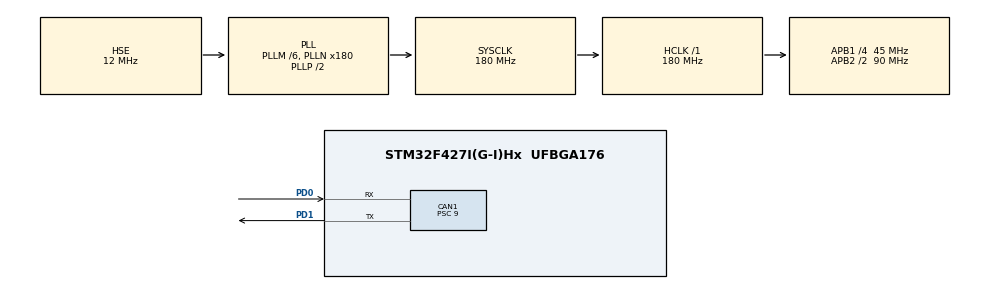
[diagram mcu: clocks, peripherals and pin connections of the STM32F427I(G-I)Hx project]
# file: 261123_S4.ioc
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CAN1.BS1=CAN_BS1_2TQ
CAN1.BS2=CAN_BS2_2TQ
CAN1.CalculateBaudRate=1000000
CAN1.CalculateTimeBit=1000
CAN1.CalculateTimeQuantum=200.0
CAN1.Prescaler=9
Mcu.Family=STM32F4
Mcu.Name=STM32F427I(G-I)Hx
Mcu.Package=UFBGA176
NVIC.CAN1_RX0_IRQn=true\:6\:0\:true\:false\:true\:true\:true
NVIC.PriorityGroup=NVIC_PRIORITYGROUP_4
NVIC.TIM6_DAC_IRQn=true\:6\:0\:true\:false\:true\:true\:true
PA13.Mode=Serial_Wire
PA13.Signal=SYS_JTMS-SWDIO
PA14.Mode=Serial_Wire
PA14.Signal=SYS_JTCK-SWCLK
PC14/OSC32_IN.Mode=LSE-External-Oscillator
PC14/OSC32_IN.Signal=RCC_OSC32_IN
PC15/OSC32_OUT.Mode=LSE-External-Oscillator
PC15/OSC32_OUT.Signal=RCC_OSC32_OUT
PD0.Mode=CAN_Activate
PD0.Signal=CAN1_RX
PD1.Mode=CAN_Activate
PD1.Signal=CAN1_TX
PH0/OSC_IN.Mode=HSE-External-Oscillator
PH0/OSC_IN.Signal=RCC_OSC_IN
PH1/OSC_OUT.Mode=HSE-External-Oscillator
PH1/OSC_OUT.Signal=RCC_OSC_OUT
ProjectManager.HeapSize=0x200
ProjectManager.StackSize=0x400
ProjectManager.TargetToolchain=MDK-ARM V5.32
RCC.48MHZClocksFreq_Value=90000000
RCC.AHBFreq_Value=180000000
RCC.APB1CLKDivider=RCC_HCLK_DIV4
RCC.APB1Freq_Value=45000000
RCC.APB1TimFreq_Value=90000000
RCC.APB2CLKDivider=RCC_HCLK_DIV2
RCC.APB2Freq_Value=90000000
RCC.APB2TimFreq_Value=180000000
RCC.CortexFreq_Value=180000000
RCC.HCLKFreq_Value=180000000
RCC.HSE_VALUE=12000000
RCC.HSI_VALUE=16000000
RCC.PLLM=6
RCC.PLLN=180
RCC.PLLSourceVirtual=RCC_PLLSOURCE_HSE
RCC.SYSCLKFreq_VALUE=180000000
RCC.SYSCLKSource=RCC_SYSCLKSOURCE_PLLCLK
RCC.VCOOutputFreq_Value=360000000
TIM6.Period=19
TIM6.Prescaler=4499
VP_TIM6_VS_ClockSourceINT.Mode=Enable_Timer
board=custom

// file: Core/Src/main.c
/* USER CODE BEGIN Header */
/**
  ******************************************************************************
  * @file           : main.c
  * @brief          : Main program body
  ******************************************************************************
  * @attention
  *
  * Copyright (c) 2026 STMicroelectronics.
  * All rights reserved.
  *
  * This software is licensed under terms that can be found in the LICENSE file
  * in the root directory of this software component.
  * If no LICENSE file comes with this software, it is provided AS-IS.
  *
  ******************************************************************************
  */
/* USER CODE END Header */
#include "main.h"
#include "can.h"
#include "tim.h"
#include "gpio.h"

/* USER CODE BEGIN PV */
CAN_FilterTypeDef h;
CAN_TxHeaderTypeDef th;
uint32_t mailbox;
int16_t last_angle[4];
int32_t total_count[4];
typedef struct{
	uint16_t angle;
	int16_t rpm;
	int16_t current;
	uint8_t temperature;
}Motor_t;
Motor_t motor[4];
/* USER CODE END PV */

void SystemClock_Config(void);

/* USER CODE BEGIN 0 */
void round_count(int i, int16_t angle){
	int16_t delta = angle - last_angle[i];
	if(delta > 4096){delta -= 8192;}
	if(delta < -4096){delta += 8192;}
	total_count[i] += delta;
	last_angle[i] = angle;
}

void CAN_Send_Message(int16_t c1, int16_t c2, int16_t c3, int16_t c4){

	th.StdId = 0x200;
	th.ExtId = 0x000;
	th.IDE = CAN_ID_STD;
	th.RTR = CAN_RTR_DATA;
	th.DLC = 8;
	uint8_t send_buf[8] = {0};
	send_buf[0] = (uint8_t)(c1 >> 8);
	send_buf[1] = (uint8_t)c1;
	send_buf[2] = (uint8_t)(c2 >> 8);
	send_buf[3] = (uint8_t)c2;
	send_buf[4] = (uint8_t)(c3 >> 8);
	send_buf[5] = (uint8_t)c3;
	send_buf[6] = (uint8_t)(c4 >> 8);
	send_buf[7] = (uint8_t)c4;
	HAL_CAN_AddTxMessage(&hcan1, &th, send_buf, &mailbox);
}

/* USER CODE END 0 */

int main(void)
{

  /* MCU Configuration--------------------------------------------------------*/

  /* Reset of all peripherals, Initializes the Flash interface and the Systick. */
  HAL_Init();

  /* Configure the system clock */
  SystemClock_Config();

  /* Initialize all configured peripherals */
  MX_GPIO_Init();
  MX_CAN1_Init();
  MX_TIM6_Init();
  /* USER CODE BEGIN 2 */

	h.FilterIdHigh = (0x201 & 0x7F8) << 5;
	h.FilterIdLow = 0x000;
	h.FilterMaskIdHigh = 0x7F8 << 5;
	h.FilterMaskIdLow = 0;
	h.FilterFIFOAssignment = CAN_RX_FIFO0;
	h.FilterBank = 1;
	h.FilterMode = 	CAN_FILTERMODE_IDMASK;
	h.FilterScale = CAN_FILTERSCALE_16BIT;
	h.FilterActivation = ENABLE;
	h.SlaveStartFilterBank = 14;
	HAL_CAN_ConfigFilter(&hcan1, &h);
	HAL_CAN_Start(&hcan1);
	HAL_CAN_ActivateNotification(&hcan1, CAN_IT_RX_FIFO0_MSG_PENDING);
	HAL_TIM_Base_Start_IT(&htim6);
  /* USER CODE END 2 */

  /* Infinite loop */
  while (1)
  {

  }
}

void SystemClock_Config(void)
{
  RCC_OscInitTypeDef RCC_OscInitStruct = {0};
  RCC_ClkInitTypeDef RCC_ClkInitStruct = {0};

  /** Configure the main internal regulator output voltage
  */
  __HAL_RCC_PWR_CLK_ENABLE();
  __HAL_PWR_VOLTAGESCALING_CONFIG(PWR_REGULATOR_VOLTAGE_SCALE1);
  /** Initializes the RCC Oscillators according to the specified parameters
  * in the RCC_OscInitTypeDef structure.
  */
  RCC_OscInitStruct.OscillatorType = RCC_OSCILLATORTYPE_HSE;
  RCC_OscInitStruct.HSEState = RCC_HSE_ON;
  RCC_OscInitStruct.PLL.PLLState = RCC_PLL_ON;
  RCC_OscInitStruct.PLL.PLLSource = RCC_PLLSOURCE_HSE;
  RCC_OscInitStruct.PLL.PLLM = 6;
  RCC_OscInitStruct.PLL.PLLN = 180;
  RCC_OscInitStruct.PLL.PLLP = RCC_PLLP_DIV2;
  RCC_OscInitStruct.PLL.PLLQ = 4;
  if (HAL_RCC_OscConfig(&RCC_OscInitStruct) != HAL_OK)
  {
    Error_Handler();
  }
  /** Activate the Over-Drive mode
  */
  if (HAL_PWREx_EnableOverDrive() != HAL_OK)
  {
    Error_Handler();
  }
  /** Initializes the CPU, AHB and APB buses clocks
  */
  RCC_ClkInitStruct.ClockType = RCC_CLOCKTYPE_HCLK|RCC_CLOCKTYPE_SYSCLK
                              |RCC_CLOCKTYPE_PCLK1|RCC_CLOCKTYPE_PCLK2;
  RCC_ClkInitStruct.SYSCLKSource = RCC_SYSCLKSOURCE_PLLCLK;
  RCC_ClkInitStruct.AHBCLKDivider = RCC_SYSCLK_DIV1;
  RCC_ClkInitStruct.APB1CLKDivider = RCC_HCLK_DIV4;
  RCC_ClkInitStruct.APB2CLKDivider = RCC_HCLK_DIV2;

  if (HAL_RCC_ClockConfig(&RCC_ClkInitStruct, FLASH_LATENCY_5) != HAL_OK)
  {
    Error_Handler();
  }
}

/* USER CODE BEGIN 4 */
void HAL_TIM_PeriodElapsedCallback(TIM_HandleTypeDef *htim){
	if(htim->Instance != TIM6)return;
	CAN_Send_Message(500, 500, 500, 500);
}
void HAL_CAN_RxFifo0MsgPendingCallback(CAN_HandleTypeDef *hcan){
	uint8_t data[8];
	CAN_RxHeaderTypeDef rh;
	HAL_CAN_GetRxMessage(&hcan1, CAN_RX_FIFO0, &rh, data);
	int i = rh.StdId - 0x201;
	if(i > 3)return;
	motor[i].angle = (uint16_t)(data[0] << 8) | data[1];
	motor[i].rpm = (int16_t)(data[2] << 8) | data[3];
	motor[i].current = (int16_t)(data[4] << 8) | data[5];
	motor[i].temperature = (uint8_t)data[6];
	for(int i = 0; i < 4; i++){
	round_count(i, motor[i].angle);
	}
}
/* USER CODE END 4 */

void Error_Handler(void)
{
  __disable_irq();
  while (1)
  {
  }
}
